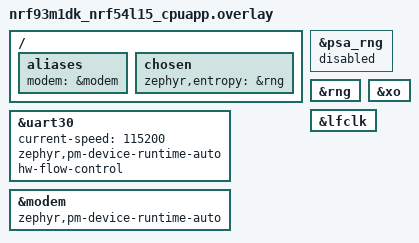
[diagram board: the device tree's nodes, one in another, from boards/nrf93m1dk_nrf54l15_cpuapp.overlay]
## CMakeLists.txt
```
#
# Copyright (c) 2026 Nordic Semiconductor ASA
#
# SPDX-License-Identifier: LicenseRef-Nordic-5-Clause
#

cmake_minimum_required(VERSION 3.20.0)

find_package(Zephyr REQUIRED HINTS $ENV{ZEPHYR_BASE})
project(ppp_shell)

# NORDIC SDK APP START
target_sources(app PRIVATE src/main.c)
# NORDIC SDK APP END
```

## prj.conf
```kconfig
#
# Copyright (c) 2026 Nordic Semiconductor ASA
#
# SPDX-License-Identifier: LicenseRef-Nordic-5-Clause
#

# Networking
CONFIG_NETWORKING=y
CONFIG_NET_NATIVE=y
CONFIG_NET_L2_PPP=y
CONFIG_NET_L2_ETHERNET=n
CONFIG_NET_IPV4=y
CONFIG_NET_IPV6=y
CONFIG_NET_UDP=y
CONFIG_NET_TCP=y
CONFIG_NET_SOCKETS=y
CONFIG_NET_CONTEXT_RCVTIMEO=y
CONFIG_ZVFS_POLL_MAX=20
CONFIG_ZVFS_OPEN_MAX=20
CONFIG_POSIX_API=y

# Performance testing
CONFIG_NET_ZPERF=y
CONFIG_NET_PKT_RX_COUNT=20
CONFIG_NET_PKT_TX_COUNT=20
CONFIG_NET_BUF_RX_COUNT=40
CONFIG_NET_BUF_TX_COUNT=40
CONFIG_NET_BUF_DATA_SIZE=256

# DNS
CONFIG_DNS_RESOLVER=y
CONFIG_DNS_RESOLVER_MAX_SERVERS=4
CONFIG_NET_L2_PPP_OPTION_DNS_USE=y

# Network management
CONFIG_NET_MGMT=y
CONFIG_NET_MGMT_EVENT=y
CONFIG_NET_CONNECTION_MANAGER=y

# Modem driver
CONFIG_MODEM=y
CONFIG_MODEM_CELLULAR=y
CONFIG_PM_DEVICE=y
CONFIG_PM_DEVICE_RUNTIME=y
CONFIG_PM_DEVICE_RUNTIME_USE_DEDICATED_WQ=y

# Shell utilities
CONFIG_SHELL=y
CONFIG_NET_SHELL=y
CONFIG_DEVICE_SHELL=y
CONFIG_PM_DEVICE_SHELL=y
CONFIG_NET_MGMT_EVENT_MONITOR=y
CONFIG_NET_MGMT_EVENT_MONITOR_AUTO_START=y
CONFIG_GPIO=y
CONFIG_GPIO_SHELL=y
CONFIG_I2C=y
CONFIG_I2C_SHELL=y
CONFIG_INPUT=y
CONFIG_SENSOR_SHELL=y
CONFIG_SHELL_WILDCARD=n
CONFIG_MODEM_AT_SHELL=y
CONFIG_MODEM_AT_USER_PIPE_IDX=0

# Logging
CONFIG_LOG=y
CONFIG_MODEM_CMUX_LOG_LEVEL_INF=y
CONFIG_MODEM_MODULES_LOG_LEVEL_INF=y

# AT channel over CMUX user pipe
CONFIG_MODEM_CELLULAR_USER_PIPE_BUFFER_SIZES=1024
CONFIG_MODEM_AT_SHELL_CHAT_RECEIVE_BUF_SIZE=256
```

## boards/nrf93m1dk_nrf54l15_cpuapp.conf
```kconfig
#
# Copyright (c) 2026 Nordic Semiconductor ASA
#
# SPDX-License-Identifier: LicenseRef-Nordic-5-Clause
#

# Use UART async API with PM_RUNTIME.
CONFIG_UART_INTERRUPT_DRIVEN=n
CONFIG_UART_ASYNC_API=y
CONFIG_SHELL_BACKEND_SERIAL_API_ASYNC=y
CONFIG_MODEM_BACKEND_UART_ASYNC_HWFC=y
CONFIG_MODEM_BACKEND_UART_ASYNC_RECEIVE_IDLE_TIMEOUT_MS=1

CONFIG_MODEM_CMUX_MTU=127
CONFIG_MODEM_CMUX_WORK_BUFFER_SIZE_EXTRA=532
CONFIG_MODEM_CELLULAR_UART_BUFFER_SIZES=532
CONFIG_MODEM_CMUX_MSC_FC_THRESHOLD=32
```

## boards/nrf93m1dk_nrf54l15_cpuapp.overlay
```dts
/*
 * Copyright (c) 2026 Nordic Semiconductor ASA
 *
 * SPDX-License-Identifier: LicenseRef-Nordic-5-Clause
 */

/ {
	aliases {
		modem = &modem;
	};

	chosen {
		zephyr,entropy = &rng;
	};
};

&uart30 {
	status = "okay";
	current-speed = <115200>;
	zephyr,pm-device-runtime-auto;
	hw-flow-control;
};

&modem {
	status = "okay";
	zephyr,pm-device-runtime-auto;
};

&psa_rng {
	status = "disabled";
};

&rng {
	status = "okay";
};

&xo {
	status = "okay";
};

&lfclk {
	status = "okay";
};
```

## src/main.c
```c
/*
 * Copyright (c) 2026 Nordic Semiconductor ASA
 *
 * SPDX-License-Identifier: LicenseRef-Nordic-5-Clause
 */
#include <zephyr/drivers/gpio.h>
#include <zephyr/device.h>

static const struct gpio_dt_spec led_green = GPIO_DT_SPEC_GET(DT_ALIAS(led2), gpios);

int main(void)
{
	gpio_pin_configure_dt(&led_green, GPIO_OUTPUT_ACTIVE);
	return 0;
}
```
